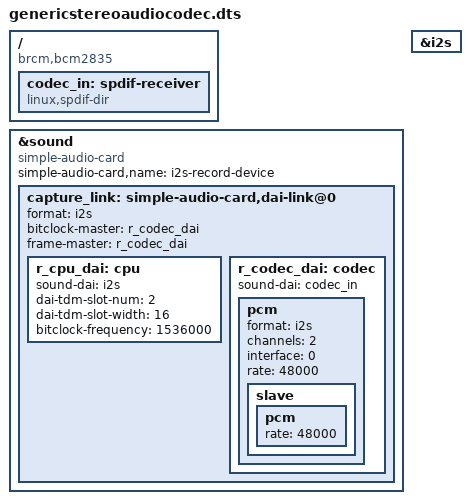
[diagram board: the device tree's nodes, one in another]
/dts-v1/;
/plugin/;

/ {
    compatible = "brcm,bcm2835";

    fragment@0 {
        target = <&sound>;
        __overlay__ {
            compatible = "simple-audio-card";
            simple-audio-card,name = "i2s-record-device";
            status = "okay";

            capture_link: simple-audio-card,dai-link@0 {
                format = "i2s";
                bitclock-master = <&r_codec_dai>;
                frame-master = <&r_codec_dai>;

                r_cpu_dai: cpu {
                    sound-dai = <&i2s>;
                    dai-tdm-slot-num = <2>;
                    dai-tdm-slot-width = <16>;
                    // Set the bitclock frequency for 16-bit, 48000 Hz
                    bitclock-frequency = <1536000>;
                };

                r_codec_dai: codec {
                    sound-dai = <&codec_in>;
                    pcm {
                        format = "i2s";
                        channels = <2>;
                        interface = <0>;
                        rate = <48000>; // Sample rate of 48000 Hz
                        slave {
                            pcm {
                                rate = <48000>; // Slave PCM rate
                            };
                        };
                    };
                };
            };
        };
    };

    fragment@1 {
        target-path = "/";
        __overlay__ {
            codec_in: spdif-receiver {
                #address-cells = <0>;
                #size-cells = <0>;
                #sound-dai-cells = <0>;
                compatible = "linux,spdif-dir";
                status = "okay";
            };
        };
    };

    fragment@2 {
        target = <&i2s>;
        __overlay__ {
            status = "okay";
        };
    };
};
